VERSION ""

NS_ :

BS_:

BU_: Tester FRBE DMU CBM ELC ZGW

BO_ 928 VehicleState: 1 ZGW
 SG_ VehicleStatus : 0|4@1+ (1,0) [0|15] ""  FRBE,ELC,DMU,CBM

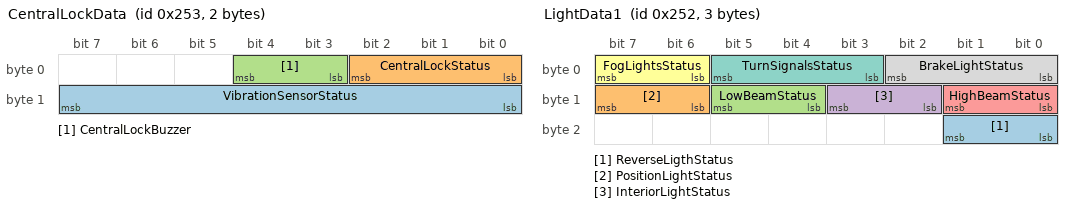
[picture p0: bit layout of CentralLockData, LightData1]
BO_ 595 CentralLockData: 2 FRBE
 SG_ VibrationSensorStatus : 8|8@1+ (1,0) [0|255] ""  ZGW
 SG_ CentralLockStatus : 0|3@1+ (1,0) [0|7] ""  ZGW
 SG_ CentralLockBuzzer : 3|2@1+ (1,0) [0|3] ""  ZGW

BO_ 594 LightData1: 3 FRBE
 SG_ ReverseLigthStatus : 16|2@1+ (1,0) [0|3] ""  ZGW
 SG_ PositionLightStatus : 14|2@1+ (1,0) [0|3] ""  ZGW
 SG_ LowBeamStatus : 12|2@1+ (1,0) [0|3] ""  ZGW
 SG_ InteriorLightStatus : 10|2@1+ (1,0) [0|3] ""  ZGW
 SG_ HighBeamStatus : 8|2@1+ (1,0) [0|3] ""  ZGW
 SG_ FogLightsStatus : 6|2@1+ (1,0) [0|3] ""  ZGW
 SG_ TurnSignalsStatus : 3|3@1+ (1,0) [0|7] ""  ZGW
 SG_ BrakeLightStatus : 0|3@1+ (1,0) [0|7] ""  ZGW

BO_ 545 DisplayOutTemp: 4 ZGW
 SG_ CommandDisplayOutsideTemperature : 0|32@1- (1,0) [-3.4E+38|3.4E+38] ""  DMU

BO_ 576 StatusActuator: 2 CBM
 SG_ StatusWipers : 8|3@1+ (1,0) [0|7] ""  ZGW
 SG_ StatusDoors : 0|6@1+ (1,0) [0|63] ""  ZGW

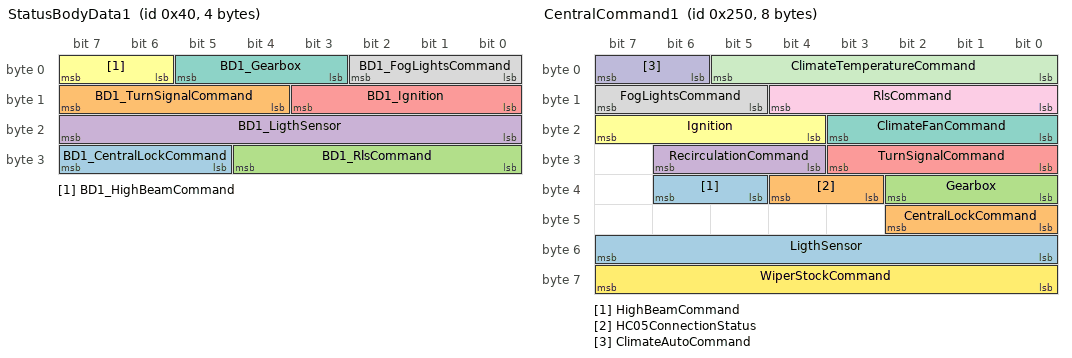
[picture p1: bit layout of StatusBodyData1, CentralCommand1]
BO_ 64 StatusBodyData1: 4 ZGW
 SG_ BD1_CentralLockCommand : 29|3@1+ (1,0) [0|7] ""  FRBE,DMU
 SG_ BD1_TurnSignalCommand : 12|4@1+ (1,0) [0|15] ""  FRBE,DMU
 SG_ BD1_RlsCommand : 24|5@1+ (1,0) [0|31] ""  FRBE,DMU
 SG_ BD1_LigthSensor : 16|8@1+ (1,0) [0|255] ""  FRBE,DMU
 SG_ BD1_Ignition : 8|4@1+ (1,0) [0|15] ""  FRBE,DMU
 SG_ BD1_HighBeamCommand : 6|2@1+ (1,0) [0|3] ""  FRBE,DMU
 SG_ BD1_Gearbox : 3|3@1+ (1,0) [0|7] ""  FRBE,DMU
 SG_ BD1_FogLightsCommand : 0|3@1+ (1,0) [0|7] ""  FRBE,DMU

BO_ 593 OutsideTemperatureStatus: 4 CBM
 SG_ OutsideTemperature : 0|32@1- (1,0) [-3.4E+38|3.4E+38] ""  ZGW

BO_ 592 CentralCommand1: 8 CBM
 SG_ HighBeamCommand : 37|2@1+ (1,0) [0|3] ""  ZGW
 SG_ HC05ConnectionStatus : 35|2@1+ (1,0) [0|3] ""  ZGW
 SG_ Gearbox : 32|3@1+ (1,0) [0|7] ""  ZGW
 SG_ RecirculationCommand : 28|3@1+ (1,0) [0|7] ""  ZGW
 SG_ TurnSignalCommand : 24|4@1+ (1,0) [0|15] ""  ZGW
 SG_ Ignition : 20|4@1+ (1,0) [0|15] ""  ZGW
 SG_ ClimateFanCommand : 16|4@1+ (1,0) [0|15] ""  ZGW
 SG_ FogLightsCommand : 13|3@1+ (1,0) [0|7] ""  ZGW
 SG_ RlsCommand : 8|5@1+ (1,0) [0|31] ""  ZGW
 SG_ ClimateAutoCommand : 6|2@1+ (1,0) [0|3] ""  ZGW
 SG_ ClimateTemperatureCommand : 0|6@1+ (1,0) [0|63] ""  ZGW
 SG_ WiperStockCommand : 56|8@1+ (1,0) [0|255] ""  ZGW
 SG_ LigthSensor : 48|8@1+ (1,0) [0|255] ""  ZGW
 SG_ CentralLockCommand : 40|3@1+ (1,0) [0|7] ""  ZGW

BO_ 513 DmuStatus: 1 DMU
 SG_ DisplayCameraStatus : 0|8@1+ (1,0) [0|255] ""  ZGW

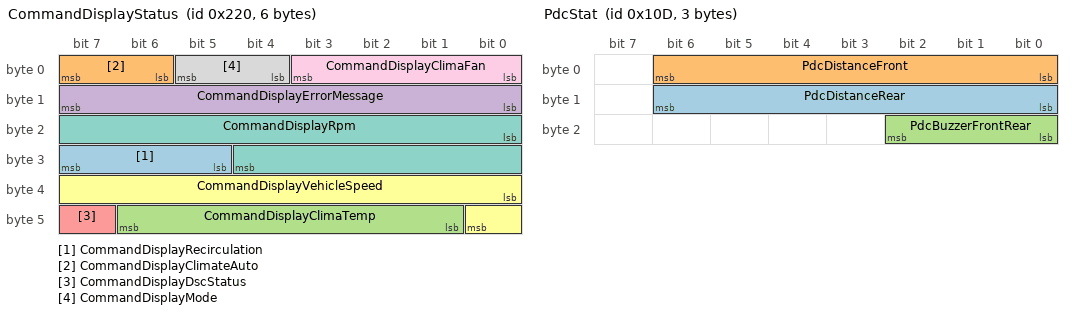
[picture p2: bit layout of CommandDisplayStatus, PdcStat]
BO_ 544 CommandDisplayStatus: 6 ZGW
 SG_ CommandDisplayRecirculation : 29|3@1+ (1,0) [0|7] ""  DMU
 SG_ CommandDisplayClimateAuto : 6|2@1+ (1,0) [0|3] ""  DMU
 SG_ CommandDisplayClimaTemp : 41|6@1+ (1,0) [0|31] ""  DMU
 SG_ CommandDisplayErrorMessage : 8|8@1+ (1,0) [0|255] ""  DMU
 SG_ CommandDisplayDscStatus : 47|1@1+ (1,0) [0|1] ""  DMU
 SG_ CommandDisplayVehicleSpeed : 32|9@1+ (1,0) [0|511] ""  DMU
 SG_ CommandDisplayRpm : 16|13@1+ (1,0) [0|8191] ""  DMU
 SG_ CommandDisplayMode : 4|2@1+ (1,0) [0|3] ""  DMU
 SG_ CommandDisplayClimaFan : 0|4@1+ (1,0) [0|15] ""  DMU

BO_ 1782 BattFullStat: 8 ELC
 SG_ RuntimeRemaining : 32|32@1- (1,0) [-3.4E+38|3.4E+38] ""  ZGW
 SG_ TimeToFull : 0|32@1- (1,0) [-3.4E+38|3.4E+38] ""  ZGW

BO_ 269 PdcStat: 3 FRBE
 SG_ PdcDistanceRear : 8|7@1+ (1,0) [0|127] ""  ZGW
 SG_ PdcDistanceFront : 0|7@1+ (1,0) [0|127] ""  ZGW
 SG_ PdcBuzzerFrontRear : 16|3@1+ (1,0) [0|7] ""  ZGW

BO_ 665 Mileage: 8 DMU
 SG_ MileageTrip : 32|32@1+ (1,0) [0|4294967295] ""  ZGW
 SG_ MileageTotal : 0|32@1+ (1,0) [0|4294967295] ""  ZGW

BO_ 512 Dmu_Alive: 1 DMU
 SG_ AliveIndication : 0|1@1+ (1,0) [0|1] ""  ZGW

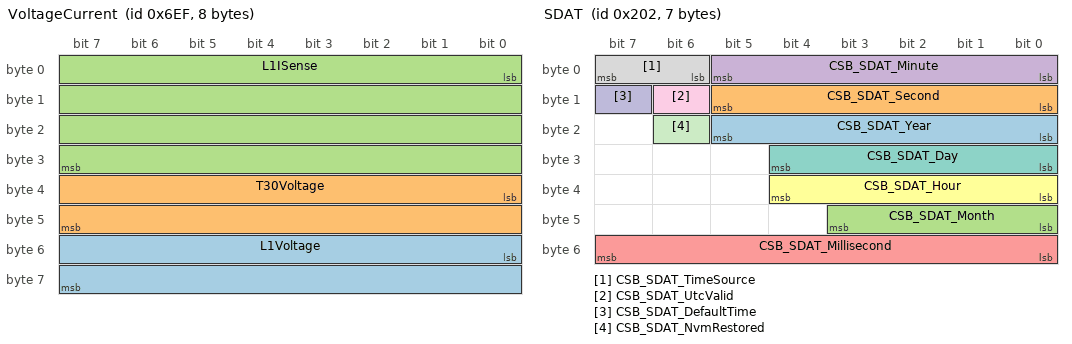
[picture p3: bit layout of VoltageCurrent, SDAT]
BO_ 1775 VoltageCurrent: 8 ELC
 SG_ L1Voltage : 48|16@1+ (1,0) [0|65535] ""  ZGW
 SG_ T30Voltage : 32|16@1+ (1,0) [0|65535] ""  ZGW
 SG_ L1ISense : 0|32@1- (1,0) [-3.4E+38|3.4E+38] ""  ZGW

BO_ 1774 TempMeas: 8 ELC
 SG_ L1Temp : 32|32@1- (1,0) [-3.4E+38|3.4E+38] ""  ZGW
 SG_ McuTemp : 0|32@1- (1,0) [-3.4E+38|3.4E+38] ""  ZGW

BO_ 514 SDAT: 7 ZGW
 SG_ CSB_SDAT_Year : 16|6@1+ (1,0) [0|63] ""  DMU,CBM,FRBE,ELC
 SG_ CSB_SDAT_Second : 8|6@1+ (1,0) [0|63] ""  DMU,CBM,FRBE,ELC
 SG_ CSB_SDAT_Month : 40|4@1+ (1,0) [0|15] ""  DMU,CBM,FRBE,ELC
 SG_ CSB_SDAT_Minute : 0|6@1+ (1,0) [0|63] ""  DMU,CBM,FRBE,ELC
 SG_ CSB_SDAT_Millisecond : 48|8@1+ (4,0) [0|1020] "ms"  DMU,CBM,FRBE,ELC
 SG_ CSB_SDAT_Hour : 32|5@1+ (1,0) [0|31] ""  DMU,CBM,FRBE,ELC
 SG_ CSB_SDAT_Day : 24|5@1+ (1,0) [0|31] ""  DMU,CBM,FRBE,ELC
 SG_ CSB_SDAT_TimeSource : 6|2@1+ (1,0) [0|3] ""  DMU,CBM,FRBE,ELC
 SG_ CSB_SDAT_UtcValid : 14|1@1+ (1,0) [0|1] ""  DMU,CBM,FRBE,ELC
 SG_ CSB_SDAT_DefaultTime : 15|1@1+ (1,0) [0|1] ""  DMU,CBM,FRBE,ELC
 SG_ CSB_SDAT_NvmRestored : 22|1@1+ (1,0) [0|1] ""  DMU,CBM,FRBE,ELC

BO_ 1023 NM3: 1 ZGW
 SG_ Nm3_Pn1 : 0|8@1+ (1,0) [0|255] ""  DMU,CBM,FRBE,ELC

BO_ 81 LoadStatus: 1 ELC
 SG_ LoadStatus : 0|1@1+ (1,0) [0|0] ""  ZGW

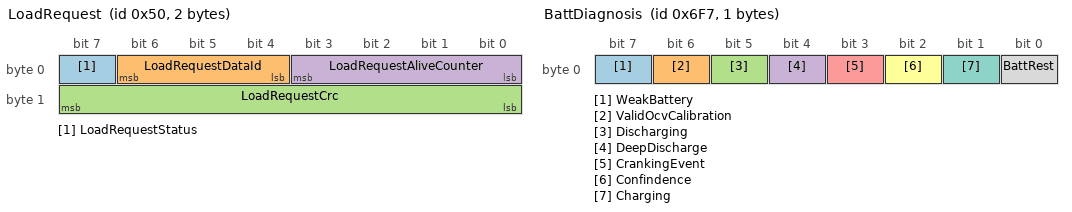
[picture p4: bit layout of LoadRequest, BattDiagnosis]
BO_ 80 LoadRequest: 2 ZGW
 SG_ LoadRequestStatus : 7|1@1+ (1,0) [0|0] ""  ELC
 SG_ LoadRequestDataId : 4|3@1+ (1,0) [0|7] ""  ELC
 SG_ LoadRequestCrc : 8|8@1+ (1,0) [0|255] ""  ELC
 SG_ LoadRequestAliveCounter : 0|4@1+ (1,0) [0|15] ""  ELC

BO_ 1776 L1_I2T_Counter: 4 ELC
 SG_ I2TCounter : 0|32@1+ (1,0) [0|4294967295] ""  ZGW

BO_ 1875 Error_706: 4 ELC
 SG_ DtcID_706 : 0|32@1+ (1,0) [0|4294967295] ""  ZGW

BO_ 1874 Error_704: 4 DMU
 SG_ DtcID_704 : 0|32@1+ (1,0) [0|4294967295] ""  ZGW

BO_ 1873 Error_702: 4 FRBE
 SG_ DtcID_702 : 0|32@1+ (1,0) [0|4294967295] ""  ZGW

BO_ 1872 Error_700: 4 CBM
 SG_ DtcID_700 : 0|32@1+ (1,0) [0|4294967295] ""  ZGW

BO_ 1779 BattSoCSoH: 8 ELC
 SG_ Soh : 32|32@1- (1,0) [-3.4E+38|3.4E+38] ""  ZGW
 SG_ SocHybrid : 0|32@1- (1,0) [-3.4E+38|3.4E+38] ""  ZGW

BO_ 1778 BattSoC: 8 ELC
 SG_ SocOcv : 32|32@1- (1,0) [-3.4E+38|3.4E+38] ""  ZGW
 SG_ SocCoulomb : 0|32@1- (1,0) [-3.4E+38|3.4E+38] ""  ZGW

BO_ 1783 BattDiagnosis: 1 ELC
 SG_ WeakBattery : 7|1@1+ (1,0) [0|1] ""  ZGW
 SG_ ValidOcvCalibration : 6|1@1+ (1,0) [0|1] ""  ZGW
 SG_ Discharging : 5|1@1+ (1,0) [0|1] ""  ZGW
 SG_ DeepDischarge : 4|1@1+ (1,0) [0|1] ""  ZGW
 SG_ CrankingEvent : 3|1@1+ (1,0) [0|1] ""  ZGW
 SG_ Confindence : 2|1@1+ (1,0) [0|1] ""  ZGW
 SG_ Charging : 1|1@1+ (1,0) [0|1] ""  ZGW
 SG_ BattRest : 0|1@1+ (1,0) [0|1] ""  ZGW

BO_ 1781 BattCurrent: 8 ELC
 SG_ AvgDischargeCurrent : 32|32@1- (1,0) [-3.4E+38|3.4E+38] ""  ZGW
 SG_ AvgChargeCurrent : 0|32@1- (1,0) [-3.4E+38|3.4E+38] ""  ZGW

BO_ 1777 BattCapDischarge: 8 ELC
 SG_ DischargeAh : 32|32@1- (1,0) [-3.4E+38|3.4E+38] ""  ZGW
 SG_ ChargeAh : 0|32@1- (1,0) [-3.4E+38|3.4E+38] ""  ZGW

BO_ 1780 BattCapRes: 8 ELC
 SG_ IntResistance : 32|32@1- (1,0) [-3.4E+38|3.4E+38] ""  ZGW
 SG_ CapacityAh : 0|32@1- (1,0) [-3.4E+38|3.4E+38] ""  ZGW

BO_TX_BU_ 1992 : Tester,ZGW;

CM_ SG_ 514 CSB_SDAT_Year "UTC year minus 2000; ZGW saturates values above 2063 to raw 63.";
CM_ SG_ 514 CSB_SDAT_Millisecond "UTC millisecond encoded with 4 ms resolution.";
CM_ SG_ 514 CSB_SDAT_TimeSource "0=default compile-time UTC, 1=UDS RoutineControl set time, 2=gPTP master, 3=invalid/unavailable.";
CM_ SG_ 514 CSB_SDAT_UtcValid "1 when UTC/calendar fields are valid for display.";
CM_ SG_ 514 CSB_SDAT_DefaultTime "1 when UTC comes from the compile-time default and shall be shown as not synchronized.";
CM_ SG_ 514 CSB_SDAT_NvmRestored "1 when UTC was restored from NvM; no powered-off elapsed time is added without an external RTC.";
VAL_ 514 CSB_SDAT_TimeSource 0 "DefaultCompileTime" 1 "UdsRoutine" 2 "GptpMaster" 3 "Invalid" ;
VAL_ 514 CSB_SDAT_UtcValid 0 "Invalid" 1 "Valid" ;
VAL_ 514 CSB_SDAT_DefaultTime 0 "NotDefault" 1 "DefaultCompileTime" ;
VAL_ 514 CSB_SDAT_NvmRestored 0 "NotRestored" 1 "RestoredFromNvM" ;
BA_DEF_  "BusType" STRING ;
BA_DEF_ BO_  "GenMsgCycleTime" INT 0 65535;
BA_DEF_DEF_  "BusType" "CAN";
BA_DEF_DEF_  "GenMsgCycleTime" 0;
BA_ "GenMsgCycleTime" BO_ 514 800;
BA_ "GenMsgCycleTime" BO_ 81 1000;
BA_ "GenMsgCycleTime" BO_ 128 5;
BA_ "GenMsgCycleTime" BO_ 129 1000;
BA_ "GenMsgCycleTime" BO_ 130 1000;
BA_ "GenMsgCycleTime" BO_ 131 1000;
BA_ "GenMsgCycleTime" BO_ 132 1000;
BA_ "GenMsgCycleTime" BO_ 133 1000;
BA_ "GenMsgCycleTime" BO_ 134 1000;
BA_ "GenMsgCycleTime" BO_ 144 5;
BA_ "GenMsgCycleTime" BO_ 145 5;
BA_ "GenMsgCycleTime" BO_ 146 100;
BA_ "GenMsgCycleTime" BO_ 256 100;
BA_ "GenMsgCycleTime" BO_ 269 100;
BA_ "GenMsgCycleTime" BO_ 512 1000;
BA_ "GenMsgCycleTime" BO_ 513 1000;
BA_ "GenMsgCycleTime" BO_ 576 100;
BA_ "GenMsgCycleTime" BO_ 592 200;
BA_ "GenMsgCycleTime" BO_ 593 1000;
BA_ "GenMsgCycleTime" BO_ 594 100;
BA_ "GenMsgCycleTime" BO_ 595 200;
BA_ "GenMsgCycleTime" BO_ 665 1000;
BA_ "GenMsgCycleTime" BO_ 1774 5;
BA_ "GenMsgCycleTime" BO_ 1775 5;
BA_ "GenMsgCycleTime" BO_ 1776 5;
BA_ "GenMsgCycleTime" BO_ 1777 1000;
BA_ "GenMsgCycleTime" BO_ 1778 1000;
BA_ "GenMsgCycleTime" BO_ 1779 1000;
BA_ "GenMsgCycleTime" BO_ 1780 1000;
BA_ "GenMsgCycleTime" BO_ 1781 5;
BA_ "GenMsgCycleTime" BO_ 1782 1000;
BA_ "GenMsgCycleTime" BO_ 1783 1000;
SIG_VALTYPE_ 545 CommandDisplayOutsideTemperature : 1;
SIG_VALTYPE_ 593 OutsideTemperature : 1;
SIG_VALTYPE_ 1782 RuntimeRemaining : 1;
SIG_VALTYPE_ 1782 TimeToFull : 1;
SIG_VALTYPE_ 1775 L1ISense : 1;
SIG_VALTYPE_ 1774 L1Temp : 1;
SIG_VALTYPE_ 1774 McuTemp : 1;
SIG_VALTYPE_ 1779 Soh : 1;
SIG_VALTYPE_ 1779 SocHybrid : 1;
SIG_VALTYPE_ 1778 SocOcv : 1;
SIG_VALTYPE_ 1778 SocCoulomb : 1;
SIG_VALTYPE_ 1781 AvgDischargeCurrent : 1;
SIG_VALTYPE_ 1781 AvgChargeCurrent : 1;
SIG_VALTYPE_ 1777 DischargeAh : 1;
SIG_VALTYPE_ 1777 ChargeAh : 1;
SIG_VALTYPE_ 1780 IntResistance : 1;
SIG_VALTYPE_ 1780 CapacityAh : 1;
